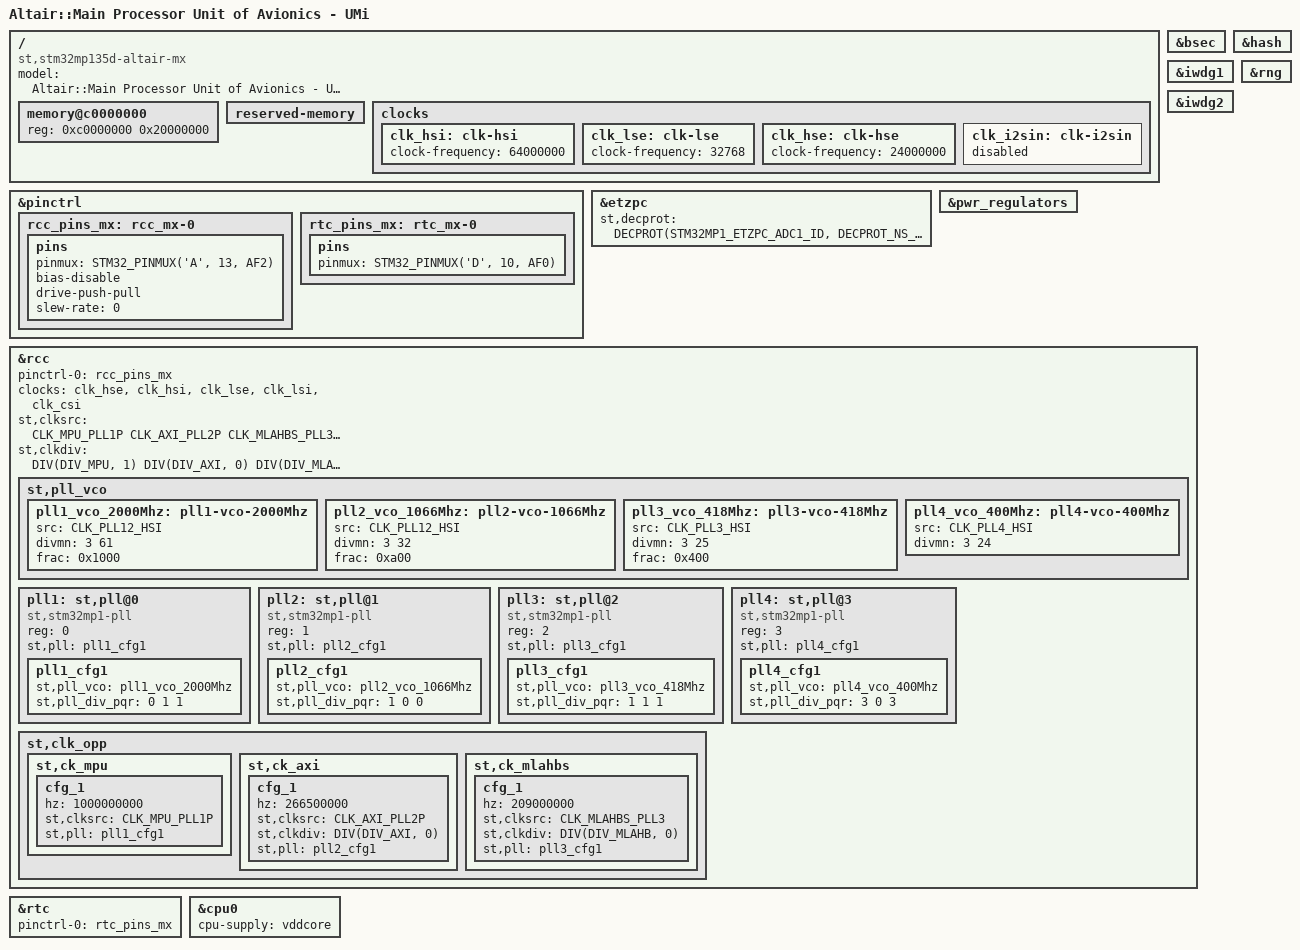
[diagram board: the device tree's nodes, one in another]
// SPDX-License-Identifier: (GPL-2.0-or-later OR BSD-3-Clause)
/*
 * Copyright (C) 2024, STMicroelectronics - All Rights Reserved
 * Author: STM32CubeMX code generation for STMicroelectronics.
 */

/* For more information on Device Tree configuration, please refer to
 * https://wiki.st.com/stm32mpu/wiki/Category:Device_tree_configuration
 */

/dts-v1/;
#include <dt-bindings/pinctrl/stm32-pinfunc.h>
#include <dt-bindings/clock/stm32mp13-clksrc.h>
#include <dt-bindings/soc/stm32mp13-etzpc.h>

#include "stm32mp135.dtsi"
#include "stm32mp13xd.dtsi"

#include "stm32mp135d-altair-mx-user.dtsi"

/* USER CODE BEGIN includes */
/* USER CODE END includes */

/ {
	model = "Altair::Main Processor Unit of Avionics - UMi";
	compatible = "st,stm32mp135d-altair-mx", "st,stm32mp135";

	memory@c0000000 {
		device_type = "memory";
		reg = <0xc0000000 0x20000000>;

		/* USER CODE BEGIN memory */
		/* USER CODE END memory */
	};

	reserved-memory {
		#address-cells = <1>;
		#size-cells = <1>;
		ranges;

		/* USER CODE BEGIN reserved-memory */
		/* USER CODE END reserved-memory */
	};

	/* USER CODE BEGIN root */
	/* USER CODE END root */

	clocks {
		/* USER CODE BEGIN clocks */
		/* USER CODE END clocks */

		clk_hsi: clk-hsi {
			clock-frequency = <64000000>;

			/* USER CODE BEGIN clk_hsi */
			/* USER CODE END clk_hsi */
		};
		clk_lse: clk-lse {
			clock-frequency = <32768>;

			/* USER CODE BEGIN clk_lse */
			/* USER CODE END clk_lse */
		};
		clk_hse: clk-hse {
			clock-frequency = <24000000>;

			/* USER CODE BEGIN clk_hse */
			/* USER CODE END clk_hse */
		};
		clk_i2sin: clk-i2sin {
			status = "disabled";

			/* USER CODE BEGIN clk_i2sin */
			/* USER CODE END clk_i2sin */
		};
	};

}; /*root*/

/*Warning: the configuration of the secured GPIOs should be added in (addons) User Section*/
&pinctrl {
	rcc_pins_mx: rcc_mx-0 {
		pins {
			pinmux = <STM32_PINMUX('A', 13, AF2)>; /* RCC_MCO_1 */
			bias-disable;
			drive-push-pull;
			slew-rate = <0>;
		};
	};

	rtc_pins_mx: rtc_mx-0 {
		pins {
			pinmux = <STM32_PINMUX('D', 10, AF0)>; /* RTC_REFIN */
		};
	};

	/* USER CODE BEGIN pinctrl */
	/* USER CODE END pinctrl */
};

&bsec{
	status = "okay";

	/* USER CODE BEGIN bsec */
	/* USER CODE END bsec */
};

&etzpc{
	status = "okay";
	st,decprot = <
	/*"Non Secured" peripherals*/
	DECPROT(STM32MP1_ETZPC_ADC1_ID, DECPROT_NS_RW, DECPROT_UNLOCK)
	DECPROT(STM32MP1_ETZPC_ADC2_ID, DECPROT_NS_RW, DECPROT_UNLOCK)
	DECPROT(STM32MP1_ETZPC_DCMIPP_ID, DECPROT_NS_RW, DECPROT_UNLOCK)
	DECPROT(STM32MP1_ETZPC_ETH1_ID, DECPROT_NS_RW, DECPROT_UNLOCK)
	DECPROT(STM32MP1_ETZPC_I2C3_ID, DECPROT_NS_RW, DECPROT_UNLOCK)
	DECPROT(STM32MP1_ETZPC_I2C4_ID, DECPROT_NS_RW, DECPROT_UNLOCK)
	DECPROT(STM32MP1_ETZPC_I2C5_ID, DECPROT_NS_RW, DECPROT_UNLOCK)
	DECPROT(STM32MP1_ETZPC_QSPI_ID, DECPROT_NS_RW, DECPROT_UNLOCK)
	DECPROT(STM32MP1_ETZPC_SDMMC1_ID, DECPROT_NS_RW, DECPROT_UNLOCK)
	DECPROT(STM32MP1_ETZPC_SDMMC2_ID, DECPROT_NS_RW, DECPROT_UNLOCK)
	DECPROT(STM32MP1_ETZPC_SPI4_ID, DECPROT_NS_RW, DECPROT_UNLOCK)
	DECPROT(STM32MP1_ETZPC_SPI5_ID, DECPROT_NS_RW, DECPROT_UNLOCK)
	DECPROT(STM32MP1_ETZPC_USART2_ID, DECPROT_NS_RW, DECPROT_UNLOCK)
	DECPROT(STM32MP1_ETZPC_OTG_ID, DECPROT_NS_RW, DECPROT_UNLOCK)
	DECPROT(STM32MP1_ETZPC_USBPHYCTRL_ID, DECPROT_NS_RW, DECPROT_UNLOCK)
	/*"NS_R S_W" peripherals*/
	DECPROT(STM32MP1_ETZPC_DDRCTRLPHY_ID, DECPROT_NS_R_S_W, DECPROT_LOCK)
	/*"Secured" peripherals*/
	DECPROT(STM32MP1_ETZPC_HASH_ID, DECPROT_S_RW, DECPROT_UNLOCK)
	DECPROT(STM32MP1_ETZPC_IWDG1_ID, DECPROT_S_RW, DECPROT_UNLOCK)
	DECPROT(STM32MP1_ETZPC_RNG_ID, DECPROT_S_RW, DECPROT_UNLOCK)
	DECPROT(STM32MP1_ETZPC_STGENC_ID, DECPROT_S_RW, DECPROT_UNLOCK)

	/*Restriction: following IDs are not managed  - please to use User-Section if needed:
		  STM32MP1_ETZPC_SRAMx_ID  STM32MP1_ETZPC_BKPSRAM_ID*/

	/* USER CODE BEGIN etzpc_decprot */
		/*STM32CubeMX generates a basic and standard configuration for ETZPC.
		Additional device configurations can be added here if needed.
		"etzpc" node could be also overloaded in "addons" User-Section.*/
	/* USER CODE END etzpc_decprot */
	>;

	/* USER CODE BEGIN etzpc */
	/* USER CODE END etzpc */
};

&hash{
	status = "okay";

	/* USER CODE BEGIN hash */
	/* USER CODE END hash */
};

&iwdg1{
	status = "okay";

	/* USER CODE BEGIN iwdg1 */
	/* USER CODE END iwdg1 */
};

&iwdg2{
	status = "okay";

	/* USER CODE BEGIN iwdg2 */
	/* USER CODE END iwdg2 */
};

&pwr_regulators{
	status = "okay";

	/* USER CODE BEGIN pwr_regulators */
	/* USER CODE END pwr_regulators */
};

&rcc{
	pinctrl-names = "default";
	pinctrl-0 = <&rcc_pins_mx>;
	status = "okay";
	clocks = <&clk_hse>, <&clk_hsi>, <&clk_lse>, <&clk_lsi>, <&clk_csi>;
	clock-names = "clk-hse", "clk-hsi", "clk-lse", "clk-lsi", "clk-csi";

	/* USER CODE BEGIN rcc */
	/* USER CODE END rcc */

	st,clksrc = <
		CLK_MPU_PLL1P
		CLK_AXI_PLL2P
		CLK_MLAHBS_PLL3
		CLK_RTC_LSI
		CLK_MCO1_CSI
		CLK_MCO2_DISABLED
		CLK_QSPI_PLL3R
		CLK_CKPER_DISABLED
		CLK_ETH1_PLL4P
		CLK_SDMMC1_HSI
		CLK_SDMMC2_HSI
		CLK_STGEN_HSI
		CLK_USBPHY_HSE
		CLK_SPI1_PLL4P
		CLK_SPI23_PLL4P
		CLK_SPI4_PCLK6
		CLK_SPI5_PCLK6
		CLK_I2C4_PCLK6
		CLK_USBO_PLL4R
		CLK_ADC1_PLL4R
		CLK_ADC2_PLL4R
		CLK_I2C12_PCLK1
		CLK_I2C3_PCLK6
		CLK_I2C5_PLL4R
		CLK_UART2_PCLK6
		CLK_UART4_PCLK1
		CLK_UART35_PCLK1
		CLK_UART78_PCLK1
		CLK_FDCAN_HSE
		CLK_RNG1_PLL4R
		CLK_DCMIPP_PLL4P
	>;
	st,clkdiv = <
		DIV(DIV_MPU, 1)
		DIV(DIV_AXI, 0)
		DIV(DIV_MLAHB, 0)
		DIV(DIV_APB1, 1)
		DIV(DIV_APB2, 1)
		DIV(DIV_APB3, 1)
		DIV(DIV_APB4, 1)
		DIV(DIV_APB5, 2)
		DIV(DIV_APB6, 1)
		DIV(DIV_RTC, 0)
		DIV(DIV_MCO1, 3)
		DIV(DIV_MCO2, 0)
	>;
	st,pll_vco {
		pll1_vco_2000Mhz: pll1-vco-2000Mhz {
			src = < CLK_PLL12_HSI >;
			divmn = < 3 61 >;
			frac = < 0x1000 >;
		};
		pll2_vco_1066Mhz: pll2-vco-1066Mhz {
			src = < CLK_PLL12_HSI >;
			divmn = < 3 32 >;
			frac = < 0xa00 >;
		};
		pll3_vco_418Mhz: pll3-vco-418Mhz {
			src = < CLK_PLL3_HSI >;
			divmn = < 3 25 >;
			frac = < 0x400 >;
		};
		pll4_vco_400Mhz: pll4-vco-400Mhz {
			src = < CLK_PLL4_HSI >;
			divmn = < 3 24 >;
		};
		/* USER CODE BEGIN rcc_st-pll_vco */
		/* USER CODE END rcc_st-pll_vco */
	};

	pll1:st,pll@0 {
		compatible = "st,stm32mp1-pll";
		reg = <0>;

		st,pll = < &pll1_cfg1 >;

		pll1_cfg1: pll1_cfg1 {
			st,pll_vco = < &pll1_vco_2000Mhz >;
			st,pll_div_pqr = < 0 1 1 >;
		};
		/* USER CODE BEGIN pll1 */
		/* USER CODE END pll1 */
	};

	pll2:st,pll@1 {
		compatible = "st,stm32mp1-pll";
		reg = <1>;

		st,pll = < &pll2_cfg1 >;

		pll2_cfg1: pll2_cfg1 {
			st,pll_vco = < &pll2_vco_1066Mhz >;
			st,pll_div_pqr = < 1 0 0 >;
		};
		/* USER CODE BEGIN pll2 */
		/* USER CODE END pll2 */
	};

	pll3:st,pll@2 {
		compatible = "st,stm32mp1-pll";
		reg = <2>;

		st,pll = < &pll3_cfg1 >;

		pll3_cfg1: pll3_cfg1 {
			st,pll_vco = < &pll3_vco_418Mhz >;
			st,pll_div_pqr = < 1 1 1 >;
		};
		/* USER CODE BEGIN pll3 */
		/* USER CODE END pll3 */
	};

	pll4:st,pll@3 {
		compatible = "st,stm32mp1-pll";
		reg = <3>;

		st,pll = < &pll4_cfg1 >;

		pll4_cfg1: pll4_cfg1 {
			st,pll_vco = < &pll4_vco_400Mhz >;
			st,pll_div_pqr = < 3 0 3 >;
		};
		/* USER CODE BEGIN pll4 */
		/* USER CODE END pll4 */
	};

	st,clk_opp {
		/* CK_MPU clock config for MP13 */
		st,ck_mpu {

			cfg_1 {
				hz = < 1000000000 >;
				st,clksrc = < CLK_MPU_PLL1P >;
				st,pll = < &pll1_cfg1 >;
			};
			/* USER CODE BEGIN rcc_st-ck_mpu */
			/* USER CODE END rcc_st-ck_mpu */
		};

		/* CK_AXI clock config for MP13 */
		st,ck_axi {

			cfg_1 {
				hz = < 266500000 >;
				st,clksrc = < CLK_AXI_PLL2P >;
				st,clkdiv = < DIV(DIV_AXI, 0) >;
				st,pll = < &pll2_cfg1 >;
			};
			/* USER CODE BEGIN rcc_st-ck_axi */
			/* USER CODE END rcc_st-ck_axi */
		};

		/* CK_MLAHBS clock config for MP13 */
		st,ck_mlahbs {

			cfg_1 {
				hz = < 209000000 >;
				st,clksrc = < CLK_MLAHBS_PLL3 >;
				st,clkdiv = < DIV(DIV_MLAHB, 0) >;
				st,pll = < &pll3_cfg1 >;
			};

			/* USER CODE BEGIN rcc_st-ck_mlahbs */
			/* USER CODE END rcc_st-ck_mlahbs */
		};
	};
};

&rng{
	status = "okay";

	/* USER CODE BEGIN rng */
	/* USER CODE END rng */
};

&rtc{
	pinctrl-names = "default";
	pinctrl-0 = <&rtc_pins_mx>;
	status = "okay";

	/* USER CODE BEGIN rtc */
	/* USER CODE END rtc */
};

/* USER CODE BEGIN addons */
/* USER CODE END addons */
&cpu0 {
	cpu-supply = <&vddcore>;
};

